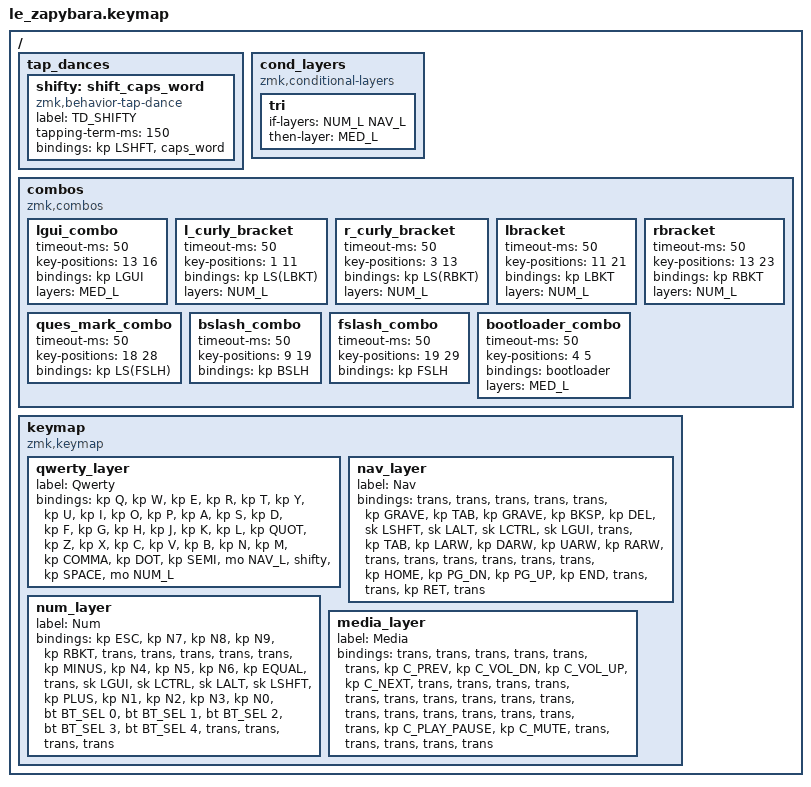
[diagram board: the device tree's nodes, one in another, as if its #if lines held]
/*
 * Copyright (c) 2020 The ZMK Contributors
 *
 * SPDX-License-Identifier: MIT
 */

#include <behaviors.dtsi>
#include <dt-bindings/zmk/keys.h>
#include <dt-bindings/zmk/bt.h>
#include <dt-bindings/zmk/backlight.h>

#define NAV_L 1
#define NUM_L 2
#define MED_L 3
#define FUN_L 4

/ {
    tap_dances {
    	shifty: shift_caps_word {
            compatible = "zmk,behavior-tap-dance";
            label = "TD_SHIFTY";
            #binding-cells = <0>;
            tapping-term-ms = <150>;
            bindings = <&kp LSHFT>, <&caps_word>;
        };
    };

    cond_layers {
        compatible = "zmk,conditional-layers";
        
        tri {
            if-layers = <NUM_L NAV_L>;
            then-layer = <MED_L>;
        };
    };

    combos {
        compatible = "zmk,combos";

        lgui_combo {
            timeout-ms = <50>;
            key-positions = <13 16>;
            bindings = <&kp LGUI>;
            layers = <MED_L>;
        };

        l_curly_bracket {
            timeout-ms = <50>;
            key-positions = <1 11>;
            bindings = <&kp LS(LBKT)>;
            layers = <NUM_L>;
        };

        r_curly_bracket {
            timeout-ms = <50>;
            key-positions = <3 13>;
            bindings = <&kp LS(RBKT)>;
            layers = <NUM_L>;
        };

        lbracket {
            timeout-ms = <50>;
            key-positions = <11 21>;
            bindings = <&kp LBKT>;
            layers = <NUM_L>;
        };

        rbracket {
            timeout-ms = <50>;
            key-positions = <13 23>;
            bindings = <&kp RBKT>;
            layers = <NUM_L>;
        };

        ques_mark_combo {
            timeout-ms = <50>;
            key-positions = <18 28>;
            bindings = <&kp LS(FSLH)>;
        };

        bslash_combo {
            timeout-ms = <50>;
            key-positions = <9 19>;
            bindings = <&kp BSLH>;
        };

        fslash_combo {
            timeout-ms = <50>;
            key-positions = <19 29>;
            bindings = <&kp FSLH>;
        };

        bootloader_combo {
            timeout-ms = <50>;
            key-positions = <4 5>;
            bindings = <&bootloader>;
            layers = <MED_L>;
        };
    };


    keymap {
        compatible = "zmk,keymap";

#ifdef QWERTY_BASE
        qwerty_layer {
            label = "Qwerty";
            bindings = <
       &kp Q      &kp W      &kp E       &kp R          &kp T         &kp Y            &kp U          &kp I       &kp O      &kp P   
       &kp A      &kp S      &kp D       &kp F          &kp G         &kp H            &kp J          &kp K       &kp L      &kp QUOT
       &kp Z      &kp X      &kp C       &kp V          &kp B         &kp N            &kp M          &kp COMMA   &kp DOT    &kp SEMI
                                     &mo NAV_L      &shifty      &kp SPACE  &mo NUM_L
            >;
        };
#else
        colemak_dhm_layer {
            label = "Base";
            bindings = <
       &kp Q      &kp W      &kp F       &kp P          &kp B         &kp J            &kp L          &kp U       &kp Y      &kp QUOT
       &kp A      &kp R      &kp S       &kp T          &kp G         &kp M            &kp N          &kp E       &kp I      &kp O   
       &kp Z      &kp X      &kp C       &kp D          &kp V         &kp K            &kp H          &kp COMMA   &kp DOT    &kp SEMI     
                                         &mo NAV_L      &shifty      &kp SPACE        &mo NUM_L
            >;
        };
#endif

        nav_layer {
            label = "Nav";
            bindings = <
       &trans     &trans     &trans      &trans          &trans       &kp GRAVE        &kp TAB        &kp GRAVE   &kp BKSP   &kp DEL
       &sk LSHFT  &sk LALT   &sk LCTRL   &sk LGUI        &trans       &kp TAB          &kp LARW       &kp DARW    &kp UARW   &kp RARW
       &trans     &trans     &trans      &trans          &trans       &trans           &kp HOME       &kp PG_DN   &kp PG_UP  &kp END
                                    &trans          &trans       &kp RET          &trans
            >;
        };

        num_layer {
            label = "Num";
            bindings = <
       &kp ESC   &kp N7     &kp N8      &kp N9          &kp RBKT      &trans        &trans         &trans      &trans     &trans
       &kp MINUS  &kp N4     &kp N5      &kp N6          &kp EQUAL     &trans        &sk LGUI       &sk LCTRL      &sk LALT     &sk LSHFT
       &kp PLUS  &kp N1     &kp N2      &kp N3          &kp N0        &bt BT_SEL 0  &bt BT_SEL 1   &bt BT_SEL 2 &bt BT_SEL 3 &bt BT_SEL 4
                                    &trans          &trans        &trans        &trans
            >;
        };

        media_layer {
            label = "Media";
            bindings = <
       &trans	   &trans     &trans      &trans          &trans       &trans           &kp C_PREV     &kp C_VOL_DN     &kp C_VOL_UP &kp C_NEXT
       &trans     &trans     &trans      &trans          &trans       &trans           &trans         &trans           &trans       &trans
       &trans     &trans     &trans      &trans          &trans       &trans           &trans         &kp C_PLAY_PAUSE &kp C_MUTE       &trans
                                    &trans          &trans       &trans           &trans
            >;
        };
    };
};
